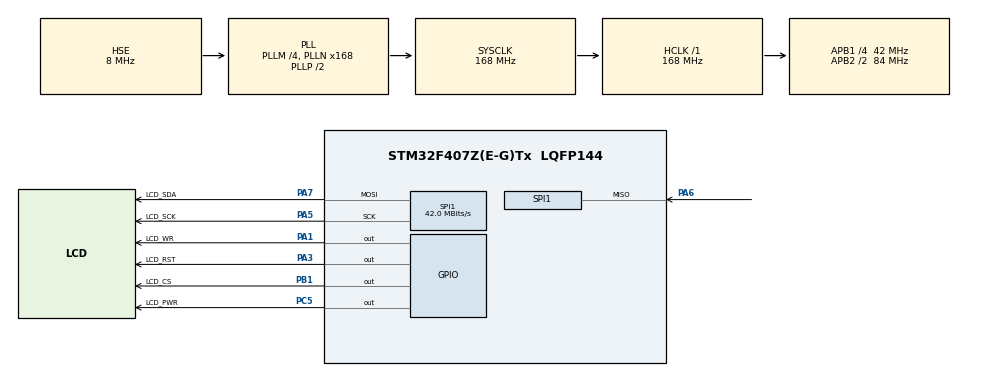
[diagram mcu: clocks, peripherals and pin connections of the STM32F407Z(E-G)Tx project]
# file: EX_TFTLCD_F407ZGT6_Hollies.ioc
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Mcu.Family=STM32F4
Mcu.Name=STM32F407Z(E-G)Tx
Mcu.Package=LQFP144
NVIC.PriorityGroup=NVIC_PRIORITYGROUP_4
PA1.GPIO_Label=LCD_WR
PA1.GPIO_ModeDefaultOutputPP=GPIO_MODE_OUTPUT_PP
PA1.GPIO_PuPd=GPIO_PULLUP
PA1.GPIO_Speed=GPIO_SPEED_FREQ_LOW
PA1.Signal=GPIO_Output
PA13.Mode=Serial_Wire
PA13.Signal=SYS_JTMS-SWDIO
PA14.Mode=Serial_Wire
PA14.Signal=SYS_JTCK-SWCLK
PA3.GPIO_Label=LCD_RST
PA3.GPIO_PuPd=GPIO_PULLUP
PA3.GPIO_Speed=GPIO_SPEED_FREQ_LOW
PA3.Signal=GPIO_Output
PA5.GPIO_Label=LCD_SCK
PA5.Mode=Full_Duplex_Master
PA5.Signal=SPI1_SCK
PA6.Mode=Full_Duplex_Master
PA6.Signal=SPI1_MISO
PA7.GPIO_Label=LCD_SDA
PA7.Mode=Full_Duplex_Master
PA7.Signal=SPI1_MOSI
PB1.GPIO_Label=LCD_CS
PB1.GPIO_PuPd=GPIO_PULLUP
PB1.GPIO_Speed=GPIO_SPEED_FREQ_LOW
PB1.PinState=GPIO_PIN_RESET
PB1.Signal=GPIO_Output
PC14-OSC32_IN.Mode=LSE-External-Oscillator
PC14-OSC32_IN.Signal=RCC_OSC32_IN
PC15-OSC32_OUT.Mode=LSE-External-Oscillator
PC15-OSC32_OUT.Signal=RCC_OSC32_OUT
PC5.GPIO_Label=LCD_PWR
PC5.GPIO_PuPd=GPIO_PULLUP
PC5.GPIO_Speed=GPIO_SPEED_FREQ_LOW
PC5.Signal=GPIO_Output
PH0-OSC_IN.Mode=HSE-External-Oscillator
PH0-OSC_IN.Signal=RCC_OSC_IN
PH1-OSC_OUT.Mode=HSE-External-Oscillator
PH1-OSC_OUT.Signal=RCC_OSC_OUT
ProjectManager.HeapSize=0x200
ProjectManager.StackSize=0x400
ProjectManager.TargetToolchain=STM32CubeIDE
RCC.48MHZClocksFreq_Value=84000000
RCC.AHBFreq_Value=168000000
RCC.APB1CLKDivider=RCC_HCLK_DIV4
RCC.APB1Freq_Value=42000000
RCC.APB1TimFreq_Value=84000000
RCC.APB2CLKDivider=RCC_HCLK_DIV2
RCC.APB2Freq_Value=84000000
RCC.APB2TimFreq_Value=168000000
RCC.CortexFreq_Value=168000000
RCC.HCLKFreq_Value=168000000
RCC.HSE_VALUE=8000000
RCC.HSI_VALUE=16000000
RCC.PLLM=4
RCC.PLLN=168
RCC.PLLSourceVirtual=RCC_PLLSOURCE_HSE
RCC.SYSCLKFreq_VALUE=168000000
RCC.SYSCLKSource=RCC_SYSCLKSOURCE_PLLCLK
RCC.VCOOutputFreq_Value=336000000
SPI1.CLKPhase=SPI_PHASE_2EDGE
SPI1.CLKPolarity=SPI_POLARITY_HIGH
SPI1.CRCCalculation=SPI_CRCCALCULATION_DISABLE
SPI1.CalculateBaudRate=42.0 MBits/s
SPI1.DataSize=SPI_DATASIZE_8BIT
SPI1.Direction=SPI_DIRECTION_2LINES
SPI1.Mode=SPI_MODE_MASTER
SPI1.VirtualType=VM_MASTER
board=custom

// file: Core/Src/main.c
/* USER CODE BEGIN Header */
/**
  ******************************************************************************
  * @file           : main.c
  * @brief          : Main program body
  ******************************************************************************
  * @attention
  *
  * Copyright (c) 2023 STMicroelectronics.
  * All rights reserved.
  *
  * This software is licensed under terms that can be found in the LICENSE file
  * in the root directory of this software component.
  * If no LICENSE file comes with this software, it is provided AS-IS.
  *
  ******************************************************************************
  */
/* USER CODE END Header */
#include "main.h"
#include "spi.h"
#include "gpio.h"

/* USER CODE BEGIN Includes */
#include "tftlcd.h"
#include "video_saved.h"
/* USER CODE END Includes */

void SystemClock_Config(void);

int main(void)
{

  /* MCU Configuration--------------------------------------------------------*/

  /* Reset of all peripherals, Initializes the Flash interface and the Systick. */
  HAL_Init();

  /* Configure the system clock */
  SystemClock_Config();

  /* Initialize all configured peripherals */
  MX_GPIO_Init();
  MX_SPI1_Init();
  /* USER CODE BEGIN 2 */
  LCD_Init();
  POINT_COLOR = WHITE;
  BACK_COLOR = BLACK;
  // LCD_Show_Image(0,0,240,240,bmp[0]);

  // LCD_Show_Image(0,120,240,120,bmp[1]);
  /* USER CODE END 2 */

  /* Infinite loop */
  while (1)
  {

    /* USER CODE BEGIN 3 */
    // for(int i = 0; i < 18; i++)
    // LCD_Show_Image(0,60,240, 120,(const uint8_t*)a[i].TDArray);
    for(int i = 0; i < 200; i++)
    {
      LCD_Show_Image(0,0,240, 32,bmp[i]);
      HAL_Delay(100);
    }
  }
  /* USER CODE END 3 */
}

void SystemClock_Config(void)
{
  RCC_OscInitTypeDef RCC_OscInitStruct = {0};
  RCC_ClkInitTypeDef RCC_ClkInitStruct = {0};

  /** Configure the main internal regulator output voltage
  */
  __HAL_RCC_PWR_CLK_ENABLE();
  __HAL_PWR_VOLTAGESCALING_CONFIG(PWR_REGULATOR_VOLTAGE_SCALE1);

  /** Initializes the RCC Oscillators according to the specified parameters
  * in the RCC_OscInitTypeDef structure.
  */
  RCC_OscInitStruct.OscillatorType = RCC_OSCILLATORTYPE_HSE;
  RCC_OscInitStruct.HSEState = RCC_HSE_ON;
  RCC_OscInitStruct.PLL.PLLState = RCC_PLL_ON;
  RCC_OscInitStruct.PLL.PLLSource = RCC_PLLSOURCE_HSE;
  RCC_OscInitStruct.PLL.PLLM = 4;
  RCC_OscInitStruct.PLL.PLLN = 168;
  RCC_OscInitStruct.PLL.PLLP = RCC_PLLP_DIV2;
  RCC_OscInitStruct.PLL.PLLQ = 4;
  if (HAL_RCC_OscConfig(&RCC_OscInitStruct) != HAL_OK)
  {
    Error_Handler();
  }

  /** Initializes the CPU, AHB and APB buses clocks
  */
  RCC_ClkInitStruct.ClockType = RCC_CLOCKTYPE_HCLK|RCC_CLOCKTYPE_SYSCLK
                              |RCC_CLOCKTYPE_PCLK1|RCC_CLOCKTYPE_PCLK2;
  RCC_ClkInitStruct.SYSCLKSource = RCC_SYSCLKSOURCE_PLLCLK;
  RCC_ClkInitStruct.AHBCLKDivider = RCC_SYSCLK_DIV1;
  RCC_ClkInitStruct.APB1CLKDivider = RCC_HCLK_DIV4;
  RCC_ClkInitStruct.APB2CLKDivider = RCC_HCLK_DIV2;

  if (HAL_RCC_ClockConfig(&RCC_ClkInitStruct, FLASH_LATENCY_5) != HAL_OK)
  {
    Error_Handler();
  }
}

void Error_Handler(void)
{
  __disable_irq();
  while (1)
  {
  }
}
